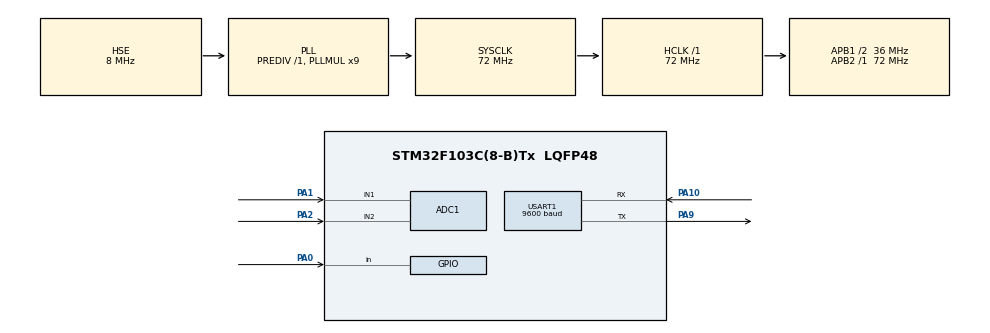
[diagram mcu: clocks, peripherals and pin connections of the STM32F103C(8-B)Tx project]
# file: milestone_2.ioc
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ADC1.Channel-1\#ChannelRegularConversion=ADC_CHANNEL_1
ADC1.NbrOfConversion=1
ADC1.NbrOfConversionFlag=1
ADC1.Rank-1\#ChannelRegularConversion=1
ADC1.SamplingTime-1\#ChannelRegularConversion=ADC_SAMPLETIME_55CYCLES_5
ADC1.master=1
Mcu.Family=STM32F1
Mcu.Name=STM32F103C(8-B)Tx
Mcu.Package=LQFP48
NVIC.PriorityGroup=NVIC_PRIORITYGROUP_4
PA0-WKUP.Signal=GPIO_Input
PA1.Signal=ADCx_IN1
PA10.Mode=Asynchronous
PA10.Signal=USART1_RX
PA2.Signal=ADCx_IN2
PA9.Mode=Asynchronous
PA9.Signal=USART1_TX
PD0-OSC_IN.Mode=HSE-External-Oscillator
PD0-OSC_IN.Signal=RCC_OSC_IN
PD1-OSC_OUT.Mode=HSE-External-Oscillator
PD1-OSC_OUT.Signal=RCC_OSC_OUT
ProjectManager.HeapSize=0x200
ProjectManager.StackSize=0x400
ProjectManager.TargetToolchain=STM32CubeIDE
RCC.ADCPresc=RCC_ADCPCLK2_DIV6
RCC.AHBFreq_Value=72000000
RCC.APB1CLKDivider=RCC_HCLK_DIV2
RCC.APB1Freq_Value=36000000
RCC.APB1TimFreq_Value=72000000
RCC.APB2Freq_Value=72000000
RCC.APB2TimFreq_Value=72000000
RCC.HCLKFreq_Value=72000000
RCC.PLLMUL=RCC_PLL_MUL9
RCC.PLLSourceVirtual=RCC_PLLSOURCE_HSE
RCC.SYSCLKFreq_VALUE=72000000
RCC.SYSCLKSource=RCC_SYSCLKSOURCE_PLLCLK
RCC.USBFreq_Value=72000000
SH.ADCx_IN1.0=ADC1_IN1,IN1
SH.ADCx_IN2.0=ADC1_IN2,IN2
USART1.BaudRate=9600
USART1.VirtualMode=VM_ASYNC
VP_SYS_VS_ND.Mode=No_Debug
board=custom

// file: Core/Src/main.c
/* USER CODE BEGIN Header */
/**
  ******************************************************************************
  * @file           : main.c
  * @brief          : Main program body
  ******************************************************************************
  */
/* USER CODE END Header */

#include "main.h"
#include <stdio.h>
#include <string.h>

ADC_HandleTypeDef hadc1;
UART_HandleTypeDef huart1;

void SystemClock_Config(void);
static void MX_GPIO_Init(void);
static void MX_ADC1_Init(void);
static void MX_USART1_UART_Init(void);

/* USER CODE BEGIN PFP */
uint32_t Read_ADC_Channel(uint32_t channel);
/* USER CODE END PFP */

/* USER CODE BEGIN 0 */

uint32_t Read_ADC_Channel(uint32_t channel)
{
    ADC_ChannelConfTypeDef sConfig = {0};

    /* Configure the requested channel as Rank 1 */
    sConfig.Channel = channel;
    sConfig.Rank = ADC_REGULAR_RANK_1;
    sConfig.SamplingTime = ADC_SAMPLETIME_55CYCLES_5;

    HAL_ADC_ConfigChannel(&hadc1, &sConfig);

    /* Start ADC */
    HAL_ADC_Start(&hadc1);

    /* Wait for conversion */
    HAL_ADC_PollForConversion(&hadc1, HAL_MAX_DELAY);

    /* Get ADC value */
    uint32_t value = HAL_ADC_GetValue(&hadc1);

    /* Stop ADC */
    HAL_ADC_Stop(&hadc1);

    return value;
}

/* USER CODE END 0 */

int main(void)
{
    /* MCU Configuration------------------------------------------------------*/

    HAL_Init();

    SystemClock_Config();

    MX_GPIO_Init();
    MX_ADC1_Init();
    MX_USART1_UART_Init();

    /* USER CODE BEGIN 2 */

    char message[100];

    /* ADC calibration */
    HAL_ADCEx_Calibration_Start(&hadc1);

    /* USER CODE END 2 */

    /* Infinite loop */
    while (1)
    {
        /* ---------------------------------------------------------
         * Read throttle potentiometer
         * PA1 = ADC1 Channel 1
         * --------------------------------------------------------- */
        uint32_t adc_throttle =
            Read_ADC_Channel(ADC_CHANNEL_1);

        /* ---------------------------------------------------------
         * Read engine temperature potentiometer
         * PA2 = ADC1 Channel 2
         * --------------------------------------------------------- */
        uint32_t adc_temp =
            Read_ADC_Channel(ADC_CHANNEL_2);

        /* ---------------------------------------------------------
         * Convert ADC values from 0-4095 to 0-100
         * --------------------------------------------------------- */
        uint32_t throttle =
            (adc_throttle * 100) / 4095;

        uint32_t temperature =
            (adc_temp * 100) / 4095;

        /* ---------------------------------------------------------
         * Prepare UART message
         * --------------------------------------------------------- */
        sprintf(message,
                "Engine Temp = %lu C | Throttle = %lu%%\r\n",
                temperature,
                throttle);

        /* ---------------------------------------------------------
         * Send message through USART1
         * --------------------------------------------------------- */
        HAL_UART_Transmit(&huart1,
                          (uint8_t *)message,
                          strlen(message),
                          HAL_MAX_DELAY);

        HAL_Delay(200);
    }
}

void SystemClock_Config(void)
{
    RCC_OscInitTypeDef RCC_OscInitStruct = {0};
    RCC_ClkInitTypeDef RCC_ClkInitStruct = {0};
    RCC_PeriphCLKInitTypeDef PeriphClkInit = {0};

    /* Initializes the RCC Oscillators */
    RCC_OscInitStruct.OscillatorType = RCC_OSCILLATORTYPE_HSE;
    RCC_OscInitStruct.HSEState = RCC_HSE_ON;
    RCC_OscInitStruct.HSEPredivValue = RCC_HSE_PREDIV_DIV1;
    RCC_OscInitStruct.HSIState = RCC_HSI_ON;

    RCC_OscInitStruct.PLL.PLLState = RCC_PLL_ON;
    RCC_OscInitStruct.PLL.PLLSource = RCC_PLLSOURCE_HSE;
    RCC_OscInitStruct.PLL.PLLMUL = RCC_PLL_MUL9;

    if (HAL_RCC_OscConfig(&RCC_OscInitStruct) != HAL_OK)
    {
        Error_Handler();
    }

    /* Initializes CPU, AHB and APB buses clocks */
    RCC_ClkInitStruct.ClockType =
        RCC_CLOCKTYPE_HCLK |
        RCC_CLOCKTYPE_SYSCLK |
        RCC_CLOCKTYPE_PCLK1 |
        RCC_CLOCKTYPE_PCLK2;

    RCC_ClkInitStruct.SYSCLKSource = RCC_SYSCLKSOURCE_PLLCLK;
    RCC_ClkInitStruct.AHBCLKDivider = RCC_SYSCLK_DIV1;
    RCC_ClkInitStruct.APB1CLKDivider = RCC_HCLK_DIV2;
    RCC_ClkInitStruct.APB2CLKDivider = RCC_HCLK_DIV1;

    if (HAL_RCC_ClockConfig(&RCC_ClkInitStruct,
                            FLASH_LATENCY_2) != HAL_OK)
    {
        Error_Handler();
    }

    /* ADC clock = PCLK2 / 6 */
    PeriphClkInit.PeriphClockSelection = RCC_PERIPHCLK_ADC;
    PeriphClkInit.AdcClockSelection = RCC_ADCPCLK2_DIV6;

    if (HAL_RCCEx_PeriphCLKConfig(&PeriphClkInit) != HAL_OK)
    {
        Error_Handler();
    }
}

static void MX_ADC1_Init(void)
{
    ADC_ChannelConfTypeDef sConfig = {0};

    /* ADC configuration */
    hadc1.Instance = ADC1;

    /*
     * We only perform ONE conversion at a time.
     * The program changes Rank 1 between Channel 1 and Channel 2.
     */
    hadc1.Init.ScanConvMode = ADC_SCAN_DISABLE;
    hadc1.Init.ContinuousConvMode = DISABLE;
    hadc1.Init.DiscontinuousConvMode = DISABLE;
    hadc1.Init.ExternalTrigConv = ADC_SOFTWARE_START;
    hadc1.Init.DataAlign = ADC_DATAALIGN_RIGHT;
    hadc1.Init.NbrOfConversion = 1;

    if (HAL_ADC_Init(&hadc1) != HAL_OK)
    {
        Error_Handler();
    }

    /* Initial channel = Channel 1 / PA1 */
    sConfig.Channel = ADC_CHANNEL_1;
    sConfig.Rank = ADC_REGULAR_RANK_1;
    sConfig.SamplingTime = ADC_SAMPLETIME_55CYCLES_5;

    if (HAL_ADC_ConfigChannel(&hadc1, &sConfig) != HAL_OK)
    {
        Error_Handler();
    }
}

static void MX_USART1_UART_Init(void)
{
    huart1.Instance = USART1;

    huart1.Init.BaudRate = 9600;
    huart1.Init.WordLength = UART_WORDLENGTH_8B;
    huart1.Init.StopBits = UART_STOPBITS_1;
    huart1.Init.Parity = UART_PARITY_NONE;
    huart1.Init.Mode = UART_MODE_TX_RX;
    huart1.Init.HwFlowCtl = UART_HWCONTROL_NONE;
    huart1.Init.OverSampling = UART_OVERSAMPLING_16;

    if (HAL_UART_Init(&huart1) != HAL_OK)
    {
        Error_Handler();
    }
}

static void MX_GPIO_Init(void)
{
    GPIO_InitTypeDef GPIO_InitStruct = {0};

    /* GPIO Ports Clock Enable */
    __HAL_RCC_GPIOD_CLK_ENABLE();
    __HAL_RCC_GPIOA_CLK_ENABLE();

    /* PA0 - not used */
    GPIO_InitStruct.Pin = GPIO_PIN_0;
    GPIO_InitStruct.Mode = GPIO_MODE_INPUT;
    GPIO_InitStruct.Pull = GPIO_NOPULL;

    HAL_GPIO_Init(GPIOA, &GPIO_InitStruct);
}

void Error_Handler(void)
{
    __disable_irq();

    while (1)
    {
    }
}
